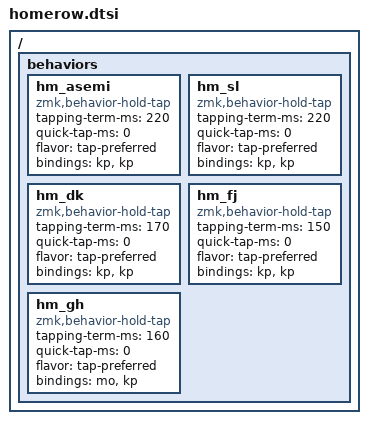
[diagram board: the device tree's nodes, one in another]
/ {
    behaviors {
        hm_asemi: hm_asemi {
        compatible = "zmk,behavior-hold-tap";
        #binding-cells = <2>;
        tapping-term-ms = <220>;
        quick-tap-ms = <0>;
        flavor = "tap-preferred";
        bindings = <&kp>, <&kp>;
        };

        hm_sl: hm_sl {
        compatible = "zmk,behavior-hold-tap";
        #binding-cells = <2>;
        tapping-term-ms = <220>;
        quick-tap-ms = <0>;
        flavor = "tap-preferred";
        bindings = <&kp>, <&kp>;
        };

        hm_dk: hm_dk {
        compatible = "zmk,behavior-hold-tap";
        #binding-cells = <2>;
        tapping-term-ms = <170>;
        quick-tap-ms = <0>;
        flavor = "tap-preferred";
        bindings = <&kp>, <&kp>;
        };

        hm_fj: hm_fj {
        compatible = "zmk,behavior-hold-tap";
        #binding-cells = <2>;
        tapping-term-ms = <150>;
        quick-tap-ms = <0>;
        flavor = "tap-preferred";
        bindings = <&kp>, <&kp>;
        };

        hm_gh: hm_gh {
        compatible = "zmk,behavior-hold-tap";
        #binding-cells = <2>;
        tapping-term-ms = <160>;
        quick-tap-ms = <0>;
        flavor = "tap-preferred";
        bindings = <&mo>, <&kp>;
        };
    };
};
